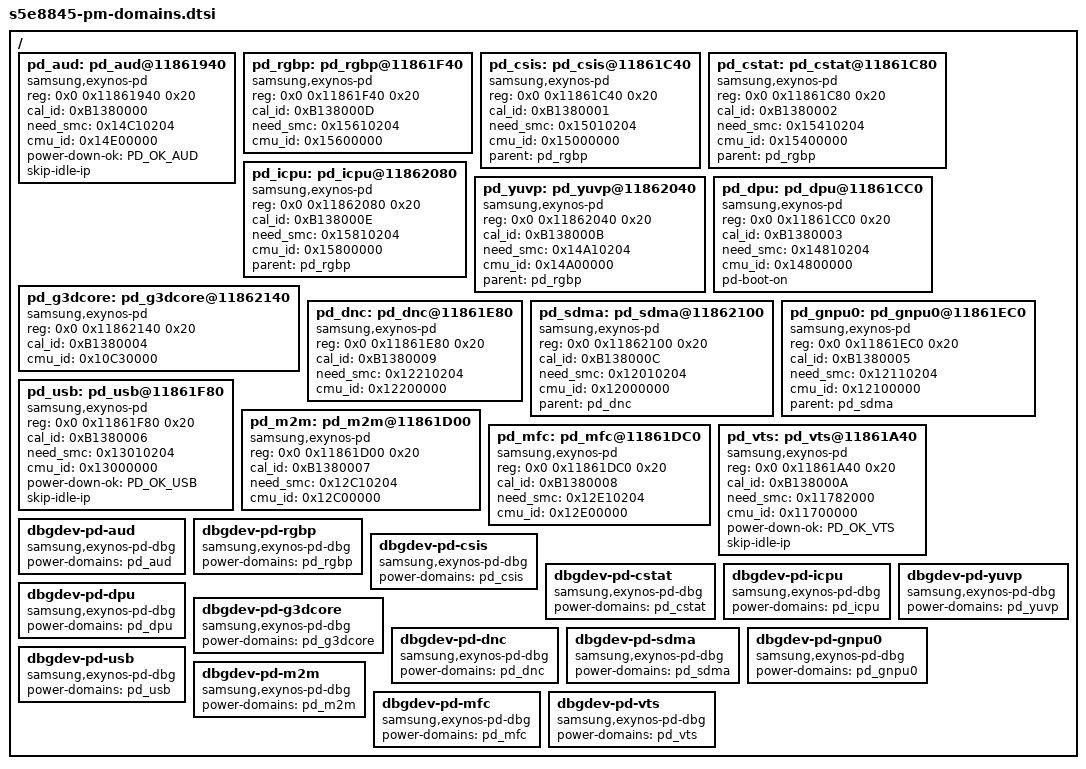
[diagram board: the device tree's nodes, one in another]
/*
* SAMSUNG  S5E8845 SoC PM Domains device tree source
*
* Copyright (c) 2023 Samsung Electronics Co., Ltd.
*      http://www.samsung.com
*
* SAMSUNG S5E8845 SoC PM domains device nodes are listed in this file.
* S5E8845 based board files can include this file and provide
* values for board specfic bindings.
*
* This program is free software; you can redistribute it and/or modify
* it under the terms of the GNU General Public License version 2 as
* published by the Free Software Foundation.
*/
#include <dt-bindings/power/exynos-power.h>

/ {
    pd_aud: pd_aud@11861940 {
        compatible = "samsung,exynos-pd";
        reg = <0x0 0x11861940 0x20>;
        cal_id = <0xB1380000>;
        need_smc = <0x14C10204>;
        cmu_id = <0x14E00000>;
        status = "okay";
        power-down-ok = <PD_OK_AUD>;
        #power-domain-cells = <0>;
        skip-idle-ip;
    };

    pd_rgbp: pd_rgbp@11861F40 {
        compatible = "samsung,exynos-pd";
        reg = <0x0 0x11861F40 0x20>;
        cal_id = <0xB138000D>;
        need_smc = <0x15610204>;
        cmu_id = <0x15600000>;
        status = "okay";
        #power-domain-cells = <0>;
    };

    pd_csis: pd_csis@11861C40 {
        compatible = "samsung,exynos-pd";
        reg = <0x0 0x11861C40 0x20>;
        cal_id = <0xB1380001>;
        need_smc = <0x15010204>;
        cmu_id = <0x15000000>;
        status = "okay";
        parent = <&pd_rgbp>;
        #power-domain-cells = <0>;
    };

    pd_cstat: pd_cstat@11861C80 {
        compatible = "samsung,exynos-pd";
        reg = <0x0 0x11861C80 0x20>;
        cal_id = <0xB1380002>;
        need_smc = <0x15410204>;
        cmu_id = <0x15400000>;
        status = "okay";
        parent = <&pd_rgbp>;
        #power-domain-cells = <0>;
    };

    pd_icpu: pd_icpu@11862080 {
        compatible = "samsung,exynos-pd";
        reg = <0x0 0x11862080 0x20>;
        cal_id = <0xB138000E>;
        need_smc = <0x15810204>;
        cmu_id = <0x15800000>;
        status = "okay";
        parent = <&pd_rgbp>;
        #power-domain-cells = <0>;
    };

    pd_yuvp: pd_yuvp@11862040 {
        compatible = "samsung,exynos-pd";
        reg = <0x0 0x11862040 0x20>;
        cal_id = <0xB138000B>;
        need_smc = <0x14A10204>;
        cmu_id = <0x14A00000>;
        status = "okay";
        parent = <&pd_rgbp>;
        #power-domain-cells = <0>;
    };

    pd_dpu: pd_dpu@11861CC0 {
        compatible = "samsung,exynos-pd";
        reg = <0x0 0x11861CC0 0x20>;
        cal_id = <0xB1380003>;
        need_smc = <0x14810204>;
        cmu_id = <0x14800000>;
        status = "okay";
        #power-domain-cells = <0>;
        pd-boot-on;
    };

    pd_g3dcore: pd_g3dcore@11862140 {
        compatible = "samsung,exynos-pd";
        reg = <0x0 0x11862140 0x20>;
        cal_id = <0xB1380004>;
        cmu_id = <0x10C30000>;
        status = "okay";
        #power-domain-cells = <0>;
    };

    pd_dnc: pd_dnc@11861E80 {
        compatible = "samsung,exynos-pd";
        reg = <0x0 0x11861E80 0x20>;
        cal_id = <0xB1380009>;
        need_smc = <0x12210204>;
        cmu_id = <0x12200000>;
        status = "okay";
        #power-domain-cells = <0>;
    };

    pd_sdma: pd_sdma@11862100 {
        compatible = "samsung,exynos-pd";
        reg = <0x0 0x11862100 0x20>;
        cal_id = <0xB138000C>;
        need_smc = <0x12010204>;
        cmu_id = <0x12000000>;
        status = "okay";
        parent = <&pd_dnc>;
        #power-domain-cells = <0>;
    };

    pd_gnpu0: pd_gnpu0@11861EC0 {
        compatible = "samsung,exynos-pd";
        reg = <0x0 0x11861EC0 0x20>;
        cal_id = <0xB1380005>;
        need_smc = <0x12110204>;
        cmu_id = <0x12100000>;
        status = "okay";
        parent = <&pd_sdma>;
        #power-domain-cells = <0>;
    };

    pd_usb: pd_usb@11861F80 {
        compatible = "samsung,exynos-pd";
        reg = <0x0 0x11861F80 0x20>;
        cal_id = <0xB1380006>;
        need_smc = <0x13010204>;
        cmu_id = <0x13000000>;
        status = "okay";
        power-down-ok = <PD_OK_USB>;
        #power-domain-cells = <0>;
        skip-idle-ip;
    };

    pd_m2m: pd_m2m@11861D00 {
        compatible = "samsung,exynos-pd";
        reg = <0x0 0x11861D00 0x20>;
        cal_id = <0xB1380007>;
        need_smc = <0x12C10204>;
        cmu_id = <0x12C00000>;
        status = "okay";
        #power-domain-cells = <0>;
    };

    pd_mfc: pd_mfc@11861DC0 {
        compatible = "samsung,exynos-pd";
        reg = <0x0 0x11861DC0 0x20>;
        cal_id = <0xB1380008>;
        need_smc = <0x12E10204>;
        cmu_id = <0x12E00000>;
        status = "okay";
        #power-domain-cells = <0>;
    };

    pd_vts: pd_vts@11861A40 {
        compatible = "samsung,exynos-pd";
        reg = <0x0 0x11861A40 0x20>;
        cal_id = <0xB138000A>;
        need_smc = <0x11782000>;
        cmu_id = <0x11700000>;
        status = "okay";
        power-down-ok = <PD_OK_VTS>;
        #power-domain-cells = <0>;
        skip-idle-ip;
    };



    dbgdev-pd-aud {
        compatible = "samsung,exynos-pd-dbg";
        power-domains = <&pd_aud>;
        };

    dbgdev-pd-rgbp {
        compatible = "samsung,exynos-pd-dbg";
        power-domains = <&pd_rgbp>;
        };

    dbgdev-pd-csis {
        compatible = "samsung,exynos-pd-dbg";
        power-domains = <&pd_csis>;
        };

    dbgdev-pd-cstat {
        compatible = "samsung,exynos-pd-dbg";
        power-domains = <&pd_cstat>;
        };

    dbgdev-pd-icpu {
        compatible = "samsung,exynos-pd-dbg";
        power-domains = <&pd_icpu>;
        };

    dbgdev-pd-yuvp {
        compatible = "samsung,exynos-pd-dbg";
        power-domains = <&pd_yuvp>;
        };

    dbgdev-pd-dpu {
        compatible = "samsung,exynos-pd-dbg";
        power-domains = <&pd_dpu>;
        };

    dbgdev-pd-g3dcore {
        compatible = "samsung,exynos-pd-dbg";
        power-domains = <&pd_g3dcore>;
        };

    dbgdev-pd-dnc {
        compatible = "samsung,exynos-pd-dbg";
        power-domains = <&pd_dnc>;
        };

    dbgdev-pd-sdma {
        compatible = "samsung,exynos-pd-dbg";
        power-domains = <&pd_sdma>;
        };

    dbgdev-pd-gnpu0 {
        compatible = "samsung,exynos-pd-dbg";
        power-domains = <&pd_gnpu0>;
        };

    dbgdev-pd-usb {
        compatible = "samsung,exynos-pd-dbg";
        power-domains = <&pd_usb>;
        };

    dbgdev-pd-m2m {
        compatible = "samsung,exynos-pd-dbg";
        power-domains = <&pd_m2m>;
        };

    dbgdev-pd-mfc {
        compatible = "samsung,exynos-pd-dbg";
        power-domains = <&pd_mfc>;
        };

    dbgdev-pd-vts {
        compatible = "samsung,exynos-pd-dbg";
        power-domains = <&pd_vts>;
        };

};
